VERSION ""

NS_ :

BS_:

BU_: AD_BATTERY_MONITOR LIGHT_ARRAY_REAR LIGHT_ARRAY_FRONT OBSTACLE_DETECTOR_REAR OBSTACLE_DETECTOR_FRONT WHEEL_REAR_RIGHT WHEEL_REAR_LEFT WHEEL_FRONT_RIGHT WHEEL_FRONT_LEFT SBUS_RECEIVER MOTOR SERVO BATTERY_MONITOR

BO_ 256 STEERING: 5 SBUS_RECEIVER
 SG_ STEERING_MODE M : 0|8@1+ (1,0) [0|0] "" Vector__XXX
 SG_ STEERING_PULSE_WIDTH m0 : 8|16@1+ (0.001,0) [500|2500] "ms" Vector__XXX
 SG_ STEERING_ANGLE m1 : 8|32@1- (1,0) [-90|90] "degrees" Vector__XXX

BO_ 257 THROTTLE: 5 SBUS_RECEIVER
 SG_ THROTTLE_MODE M : 0|8@1+ (1,0) [0|0] "" Vector__XXX
 SG_ THROTTLE_PULSE_WIDTH m0 : 8|16@1+ (0.001,0) [1000|2000] "ms" Vector__XXX

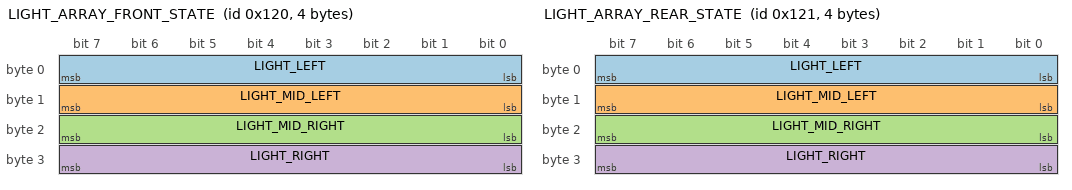
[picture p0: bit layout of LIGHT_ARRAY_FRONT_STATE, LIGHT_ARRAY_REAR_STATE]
BO_ 288 LIGHT_ARRAY_FRONT_STATE: 4 LIGHT_ARRAY_FRONT
 SG_ LIGHT_LEFT : 0|8@1+ (1,0) [0|0] "" Vector__XXX
 SG_ LIGHT_MID_LEFT : 8|8@1+ (1,0) [0|0] "" Vector__XXX
 SG_ LIGHT_MID_RIGHT : 16|8@1+ (1,0) [0|0] "" Vector__XXX
 SG_ LIGHT_RIGHT : 24|8@1+ (1,0) [0|0] "" Vector__XXX

BO_ 289 LIGHT_ARRAY_REAR_STATE: 4 LIGHT_ARRAY_REAR
 SG_ LIGHT_LEFT : 0|8@1+ (1,0) [0|0] "" Vector__XXX
 SG_ LIGHT_MID_LEFT : 8|8@1+ (1,0) [0|0] "" Vector__XXX
 SG_ LIGHT_MID_RIGHT : 16|8@1+ (1,0) [0|0] "" Vector__XXX
 SG_ LIGHT_RIGHT : 24|8@1+ (1,0) [0|0] "" Vector__XXX

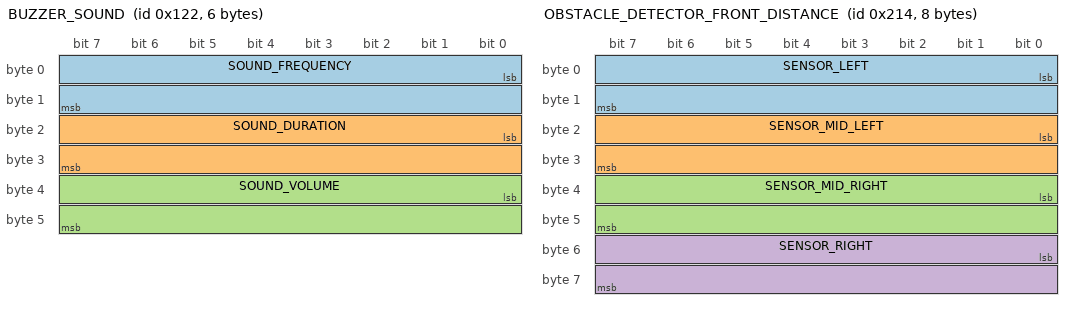
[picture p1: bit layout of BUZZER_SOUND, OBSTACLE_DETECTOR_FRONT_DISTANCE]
BO_ 290 BUZZER_SOUND: 6 Vector__XXX
 SG_ SOUND_FREQUENCY : 0|16@1+ (1,0) [0|0] "Hz" SBUS_RECEIVER
 SG_ SOUND_DURATION : 16|16@1+ (1,0) [0|0] "ms" SBUS_RECEIVER
 SG_ SOUND_VOLUME : 32|16@1+ (1,0) [0|0] "" SBUS_RECEIVER

BO_ 512 BATTERY_CELL_VOLTAGES: 7 BATTERY_MONITOR
 SG_ CELLS M : 0|8@1+ (1,0) [0|0] "" Vector__XXX
 SG_ CELL_1_VOLTAGE m0 : 8|16@1+ (1,0) [0|0] "mV" Vector__XXX
 SG_ CELL_2_VOLTAGE m0 : 24|16@1+ (1,0) [0|0] "mV" Vector__XXX
 SG_ CELL_3_VOLTAGE m0 : 40|16@1+ (1,0) [0|0] "mV" Vector__XXX
 SG_ CELL_4_VOLTAGE m1 : 8|16@1+ (1,0) [0|0] "mV" Vector__XXX
 SG_ CELL_5_VOLTAGE m1 : 24|16@1+ (1,0) [0|0] "mV" Vector__XXX
 SG_ CELL_6_VOLTAGE m1 : 40|16@1+ (1,0) [0|0] "mV" Vector__XXX

BO_ 513 REGULATED_OUTPUT: 8 Vector__XXX
 SG_ REGULATED_OUTPUT_VOLTAGE : 0|32@1+ (1,0) [0|0] "mV" Vector__XXX
 SG_ REGULATED_OUTPUT_CURRENT : 32|32@1+ (1,0) [0|0] "mA" Vector__XXX

BO_ 514 BATTERY_OUTPUT: 8 BATTERY_MONITOR
 SG_ BATTERY_OUTPUT_VOLTAGE : 0|32@1+ (1,0) [0|0] "mV" Vector__XXX
 SG_ BATTERY_OUTPUT_CURRENT : 32|32@1+ (1,0) [0|0] "mA" Vector__XXX

BO_ 515 SERVO_VOLTAGE: 2 SERVO
 SG_ SERVO_VOLTAGE : 0|16@1+ (1,0) [0|0] "mV" Vector__XXX

BO_ 516 SERVO_CURRENT: 2 SERVO
 SG_ SERVO_CURRENT : 0|16@1+ (1,0) [0|0] "mA" Vector__XXX

BO_ 517 BATTERY_VOLTAGE: 2 BATTERY_MONITOR
 SG_ BATTERY_VOLTAGE : 0|16@1+ (1,0) [0|0] "mV" Vector__XXX

BO_ 518 SERVO_POSITION: 4 SERVO
 SG_ SERVO_POSITION : 0|32@1- (1,0) [0|0] "degrees" Vector__XXX

BO_ 528 WHEEL_FRONT_LEFT_SPEED: 8 WHEEL_FRONT_LEFT
 SG_ RPM : 0|32@1- (1,0) [0|0] "" Vector__XXX
 SG_ SPEED : 32|32@1- (1,0) [0|0] "km/h" Vector__XXX

BO_ 529 WHEEL_FRONT_RIGHT_SPEED: 8 WHEEL_FRONT_RIGHT
 SG_ RPM : 0|32@1- (1,0) [0|0] "" Vector__XXX
 SG_ SPEED : 32|32@1- (1,0) [0|0] "km/h" Vector__XXX

BO_ 530 WHEEL_REAR_LEFT_SPEED: 8 WHEEL_REAR_LEFT
 SG_ RPM : 0|32@1- (1,0) [0|0] "" Vector__XXX
 SG_ SPEED : 32|32@1- (1,0) [0|0] "km/h" Vector__XXX

BO_ 531 WHEEL_REAR_RIGHT_SPEED: 8 WHEEL_REAR_RIGHT
 SG_ RPM : 0|32@1- (1,0) [0|0] "" Vector__XXX
 SG_ SPEED : 32|32@1- (1,0) [0|0] "km/h" Vector__XXX

BO_ 532 OBSTACLE_DETECTOR_FRONT_DISTANCE: 8 OBSTACLE_DETECTOR_FRONT
 SG_ SENSOR_LEFT : 0|16@1+ (1,0) [0|0] "mm" Vector__XXX
 SG_ SENSOR_MID_LEFT : 16|16@1+ (1,0) [0|0] "mm" Vector__XXX
 SG_ SENSOR_MID_RIGHT : 32|16@1+ (1,0) [0|0] "mm" Vector__XXX
 SG_ SENSOR_RIGHT : 48|16@1+ (1,0) [0|0] "mm" Vector__XXX

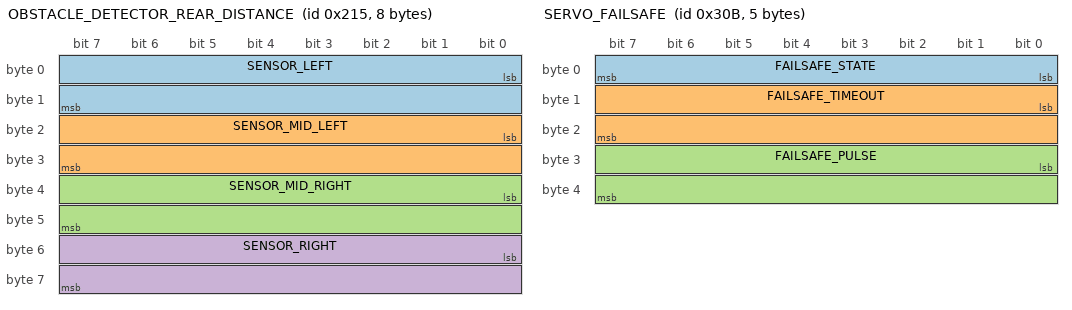
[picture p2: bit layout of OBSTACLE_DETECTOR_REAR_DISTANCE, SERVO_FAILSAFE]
BO_ 533 OBSTACLE_DETECTOR_REAR_DISTANCE: 8 OBSTACLE_DETECTOR_REAR
 SG_ SENSOR_LEFT : 0|16@1+ (1,0) [0|0] "mm" Vector__XXX
 SG_ SENSOR_MID_LEFT : 16|16@1+ (1,0) [0|0] "mm" Vector__XXX
 SG_ SENSOR_MID_RIGHT : 32|16@1+ (1,0) [0|0] "mm" Vector__XXX
 SG_ SENSOR_RIGHT : 48|16@1+ (1,0) [0|0] "mm" Vector__XXX

BO_ 768 BATTERY_JUMPER_CONFIG: 1 Vector__XXX
 SG_ JUMPER_CONFIG : 0|8@1+ (1,0) [0|0] ""  BATTERY_MONITOR

BO_ 769 BATTERY_REGULATED_OUTPUT_VOLTAGE: 4 Vector__XXX
 SG_ REGULATED_OUTPUT_VOLTAGE : 0|32@1+ (1,0) [0|0] "mV"  BATTERY_MONITOR

BO_ 770 BATTERY_OUTPUT_ON_OFF: 2 Vector__XXX
 SG_ MAIN_POWER_OUTPUT_STATE : 0|8@1+ (1,0) [0|0] ""  BATTERY_MONITOR
 SG_ REGULATED_OUTPUT_STATE : 8|8@1+ (1,0) [0|0] ""  BATTERY_MONITOR

BO_ 771 BATTERY_REPORT_FREQUENCY: 2 Vector__XXX
 SG_ REPORT_PERIOD : 0|16@1+ (1,0) [0|0] "ms"  BATTERY_MONITOR

BO_ 772 BATTERY_LOW_VOLTAGE_CUTOFF: 2 Vector__XXX
 SG_ LOW_VOLTAGE_CUTOFF : 0|16@1+ (1,0) [0|0] "mV"  BATTERY_MONITOR

BO_ 773 SERVO_SET_VOLTAGE: 2 Vector__XXX
 SG_ REQUESTED_SERVO_VOLTAGE : 0|16@1+ (1,0) [2740|10800] "mV"  SERVO

BO_ 774 SERVO_PWM_CONFIG: 2 Vector__XXX
 SG_ PWM_FREQUENCY : 0|16@1+ (1,0) [1|333] "Hz"  SERVO

BO_ 775 SERVO_REPORT_FREQUENCY: 2 Vector__XXX
 SG_ REPORT_PERIOD : 0|16@1+ (1,0) [0|0] "ms"  SERVO

BO_ 776 MOTOR_PWM_CONFIG: 2 Vector__XXX
 SG_ PWM_FREQUENCY : 0|16@1+ (1,0) [1|333] "Hz"  MOTOR

BO_ 777 SERVO_REVERSE_DIRECTION: 0 Vector__XXX

BO_ 778 MOTOR_REVERSE_DIRECTION: 0 Vector__XXX

BO_ 779 SERVO_FAILSAFE: 5 Vector__XXX
 SG_ FAILSAFE_STATE : 0|8@1+ (1,0) [0|0] ""  SERVO
 SG_ FAILSAFE_TIMEOUT : 8|16@1+ (1,0) [0|0] "ms"  SERVO
 SG_ FAILSAFE_PULSE : 24|16@1+ (0.001,0) [500|2500] "ms"  SERVO

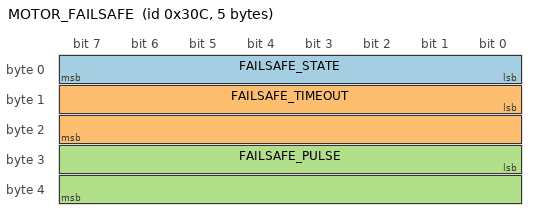
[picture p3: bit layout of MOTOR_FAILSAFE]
BO_ 780 MOTOR_FAILSAFE: 5 Vector__XXX
 SG_ FAILSAFE_STATE : 0|8@1+ (1,0) [0|0] ""  MOTOR
 SG_ FAILSAFE_TIMEOUT : 8|16@1+ (1,0) [0|0] "ms"  MOTOR
 SG_ FAILSAFE_PULSE : 24|16@1+ (0.001,0) [1000|2000] "ms"  MOTOR

BO_ 781 STEERING_SUBTRIM: 2 Vector__XXX
 SG_ SUBTRIM : 0|16@1- (0.001,0) [-500|500] "ms" Vector__XXX

BO_ 782 THROTTLE_SUBTRIM: 2 Vector__XXX
 SG_ SUBTRIM : 0|16@1- (0.001,0) [-500|500] "ms" Vector__XXX

BO_ 783 BATTERY_VBAT_OUT_OVERCURRENT_THRESHOLD: 4 Vector__XXX
 SG_ OVERCURRENT_THRESHOLD : 0|32@1+ (1,0) [0|0] "mA"  BATTERY_MONITOR

BO_ 784 BATTERY_REG_OUT_OVERCURRENT_THRESHOLD: 4 Vector__XXX
 SG_ OVERCURRENT_THRESHOLD : 0|32@1+ (1,0) [0|0] "mA"  BATTERY_MONITOR

BO_ 785 WHEEL_FRONT_LEFT_WHEEL_PARAMETERS: 8 Vector__XXX
 SG_ COG_COUNT : 0|32@1+ (1,0) [0|0] ""  WHEEL_FRONT_LEFT
 SG_ WHEEL_DIAMETER : 32|32@1- (1,0) [0|0] "m"  WHEEL_FRONT_LEFT

BO_ 786 WHEEL_FRONT_LEFT_REPORT_FREQUENCY: 2 Vector__XXX
 SG_ REPORT_PERIOD : 0|16@1+ (1,0) [0|0] "ms"  WHEEL_FRONT_LEFT

BO_ 787 WHEEL_FRONT_RIGHT_WHEEL_PARAMETERS: 8 Vector__XXX
 SG_ COG_COUNT : 0|32@1+ (1,0) [0|0] ""  WHEEL_FRONT_RIGHT
 SG_ WHEEL_DIAMETER : 32|32@1- (1,0) [0|0] "m"  WHEEL_FRONT_RIGHT

BO_ 788 WHEEL_FRONT_RIGHT_REPORT_FREQUENCY: 2 Vector__XXX
 SG_ REPORT_PERIOD : 0|16@1+ (1,0) [0|0] "ms"  WHEEL_FRONT_RIGHT

BO_ 789 WHEEL_REAR_LEFT_WHEEL_PARAMETERS: 8 Vector__XXX
 SG_ COG_COUNT : 0|32@1+ (1,0) [0|0] ""  WHEEL_REAR_LEFT
 SG_ WHEEL_DIAMETER : 32|32@1- (1,0) [0|0] "m"  WHEEL_REAR_LEFT

BO_ 790 WHEEL_REAR_LEFT_REPORT_FREQUENCY: 2 Vector__XXX
 SG_ REPORT_PERIOD : 0|16@1+ (1,0) [0|0] "ms"  WHEEL_REAR_LEFT

BO_ 791 WHEEL_REAR_RIGHT_WHEEL_PARAMETERS: 8 Vector__XXX
 SG_ COG_COUNT : 0|32@1+ (1,0) [0|0] ""  WHEEL_REAR_RIGHT
 SG_ WHEEL_DIAMETER : 32|32@1- (1,0) [0|0] "m"  WHEEL_REAR_RIGHT

BO_ 792 WHEEL_REAR_RIGHT_REPORT_FREQUENCY: 2 Vector__XXX
 SG_ REPORT_PERIOD : 0|16@1+ (1,0) [0|0] "ms"  WHEEL_REAR_RIGHT

BO_ 793 BATTERY_CELL_CALIBRATION: 2 Vector__XXX
 SG_ CELL_CALIBRATION_VOLTAGE : 0|16@1+ (1,0) [0|0] "mV"  BATTERY_MONITOR

BO_ 794 OBSTACLE_DETECTOR_FRONT_REPORT_FREQUENCY: 2 Vector__XXX
 SG_ REPORT_PERIOD : 0|16@1+ (1,0) [0|0] "ms"  OBSTACLE_DETECTOR_FRONT

BO_ 795 OBSTACLE_DETECTOR_REAR_REPORT_FREQUENCY: 2 Vector__XXX
 SG_ REPORT_PERIOD : 0|16@1+ (1,0) [0|0] "ms"  OBSTACLE_DETECTOR_REAR

BO_ 1792 BOOTLOADER_COMMAND_ACK: 5 Vector__XXX
 SG_ ACK_TYPE : 0|8@1+ (1,0) [0|0] "" Vector__XXX
 SG_ COMMAND_ID : 8|32@1+ (1,0) [0|0] "" Vector__XXX

BO_ 1793 BOOTLOADER_ENTER: 0 Vector__XXX

BO_ 1794 BOOTLOADER_EXIT: 0 Vector__XXX

BO_ 1795 BOOTLOADER_FLASH_ERASE: 4 Vector__XXX
 SG_ BYTES : 0|32@1+ (1,0) [0|0] "bytes" Vector__XXX

BO_ 1796 BOOTLOADER_FORMAT_FS: 0 Vector__XXX

BO_ 1797 BOOTLOADER_FLASH_PROGRAM: 8 Vector__XXX
 SG_ BLOCK_TRANSFER_PAGE M : 0|8@1+ (1,0) [0|0] "" Vector__XXX
 SG_ BLOCK_LENGTH m1 : 8|32@1+ (1,0) [0|0] "bytes" Vector__XXX
 SG_ BUNDLE_PAGE_COUNT m2 : 8|16@1+ (1,0) [0|0] "" Vector__XXX
 SG_ DATA_A m3 : 8|56@1+ (1,0) [0|0] "" Vector__XXX
 SG_ DATA_B m4 : 8|56@1+ (1,0) [0|0] "" Vector__XXX

BO_ 1798 BOOTLOADER_FLASH_CONFIG: 8 Vector__XXX
 SG_ BLOCK_TRANSFER_PAGE M : 0|8@1+ (1,0) [0|0] "" Vector__XXX
 SG_ BLOCK_LENGTH m1 : 8|32@1+ (1,0) [0|0] "bytes" Vector__XXX
 SG_ BUNDLE_PAGE_COUNT m2 : 8|16@1+ (1,0) [0|0] "" Vector__XXX
 SG_ DATA_A m3 : 8|56@1+ (1,0) [0|0] "" Vector__XXX
 SG_ DATA_B m4 : 8|56@1+ (1,0) [0|0] "" Vector__XXX

BO_ 1280 AD_BATTERY_CELL_VOLTAGES: 7 AD_BATTERY_MONITOR
 SG_ CELLS M : 0|8@1+ (1,0) [0|0] "" Vector__XXX
 SG_ CELL_1_VOLTAGE m0 : 8|16@1+ (1,0) [0|0] "mV" Vector__XXX
 SG_ CELL_2_VOLTAGE m0 : 24|16@1+ (1,0) [0|0] "mV" Vector__XXX
 SG_ CELL_3_VOLTAGE m0 : 40|16@1+ (1,0) [0|0] "mV" Vector__XXX
 SG_ CELL_4_VOLTAGE m1 : 8|16@1+ (1,0) [0|0] "mV" Vector__XXX
 SG_ CELL_5_VOLTAGE m1 : 24|16@1+ (1,0) [0|0] "mV" Vector__XXX
 SG_ CELL_6_VOLTAGE m1 : 40|16@1+ (1,0) [0|0] "mV" Vector__XXX

BO_ 1281 AD_REGULATED_OUTPUT: 8 AD_BATTERY_MONITOR
 SG_ REGULATED_OUTPUT_VOLTAGE : 0|32@1+ (1,0) [0|0] "mV" Vector__XXX
 SG_ REGULATED_OUTPUT_CURRENT : 32|32@1+ (1,0) [0|0] "mA" Vector__XXX

BO_ 1282 AD_BATTERY_OUTPUT: 8 AD_BATTERY_MONITOR
 SG_ BATTERY_OUTPUT_VOLTAGE : 0|32@1+ (1,0) [0|0] "mV" Vector__XXX
 SG_ BATTERY_OUTPUT_CURRENT : 32|32@1+ (1,0) [0|0] "mA" Vector__XXX

BO_ 1283 AD_BATTERY_VOLTAGE: 2 AD_BATTERY_MONITOR
 SG_ BATTERY_VOLTAGE : 0|16@1+ (1,0) [0|0] "mV" Vector__XXX

BO_ 1536 AD_BATTERY_JUMPER_CONFIG: 1 Vector__XXX
 SG_ JUMPER_CONFIG : 0|8@1+ (1,0) [0|0] ""  AD_BATTERY_MONITOR

BO_ 1537 AD_BATTERY_REGULATED_OUTPUT_VOLTAGE: 4 Vector__XXX
 SG_ REGULATED_OUTPUT_VOLTAGE : 0|32@1+ (1,0) [0|0] "mV"  AD_BATTERY_MONITOR

BO_ 1538 AD_BATTERY_OUTPUT_ON_OFF: 2 Vector__XXX
 SG_ MAIN_POWER_OUTPUT_STATE : 0|8@1+ (1,0) [0|0] ""  AD_BATTERY_MONITOR
 SG_ REGULATED_OUTPUT_STATE : 8|8@1+ (1,0) [0|0] ""  AD_BATTERY_MONITOR

BO_ 1539 AD_BATTERY_REPORT_FREQUENCY: 2 Vector__XXX
 SG_ REPORT_PERIOD : 0|16@1+ (1,0) [0|0] "ms"  AD_BATTERY_MONITOR

BO_ 1540 AD_BATTERY_LOW_VOLTAGE_CUTOFF: 2 Vector__XXX
 SG_ LOW_VOLTAGE_CUTOFF : 0|16@1+ (1,0) [0|0] "mV"  AD_BATTERY_MONITOR

BO_ 1551 AD_BATTERY_VBAT_OUT_OVERCURRENT_THRESHOLD: 4 Vector__XXX
 SG_ OVERCURRENT_THRESHOLD : 0|32@1+ (1,0) [0|0] "mA"  AD_BATTERY_MONITOR

BO_ 1552 AD_BATTERY_REG_OUT_OVERCURRENT_THRESHOLD: 4 Vector__XXX
 SG_ OVERCURRENT_THRESHOLD : 0|32@1+ (1,0) [0|0] "mA"  AD_BATTERY_MONITOR

BO_ 1553 AD_BATTERY_CELL_CALIBRATION: 2 Vector__XXX
 SG_ CELL_CALIBRATION_VOLTAGE : 0|16@1+ (1,0) [0|0] "mV"  AD_BATTERY_MONITOR

VAL_ 256 STEERING_MODE 0 "PULSE_WIDTH_MODE" 1 "ANGLE_MODE" ;
VAL_ 257 THROTTLE_MODE 0 "PULSE_WIDTH_MODE" ;
VAL_ 288 LIGHT_LEFT 0 "OFF" 1 "ON" ;
VAL_ 288 LIGHT_MID_LEFT 0 "OFF" 1 "ON" ;
VAL_ 288 LIGHT_MID_RIGHT 0 "OFF" 1 "ON" ;
VAL_ 288 LIGHT_RIGHT 0 "OFF" 1 "ON" ;
VAL_ 289 LIGHT_LEFT 0 "OFF" 1 "ON" ;
VAL_ 289 LIGHT_MID_LEFT 0 "OFF" 1 "ON" ;
VAL_ 289 LIGHT_MID_RIGHT 0 "OFF" 1 "ON" ;
VAL_ 289 LIGHT_RIGHT 0 "OFF" 1 "ON" ;
VAL_ 512 CELLS 0 "CELLS_1_TO_3" 1 "CELLS_4_TO_6" ;
VAL_ 768 JUMPER_CONFIG 0 "X11_OFF_X12_OFF" 1 "X11_ON_X12_OFF" 2 "X11_OFF_X12_ON" 3 "X11_ON_X12_ON" ;
VAL_ 770 MAIN_POWER_OUTPUT_STATE 0 "OFF" 1 "ON" ;
VAL_ 770 REGULATED_OUTPUT_STATE 0 "OFF" 1 "ON" ;
VAL_ 779 FAILSAFE_STATE 0 "OFF" 1 "ON" ;
VAL_ 780 FAILSAFE_STATE 0 "OFF" 1 "ON" ;
VAL_ 1792 ACK_TYPE 0 "ACK" 1 "NACK" ;
VAL_ 1797 BLOCK_TRANSFER_PAGE 0 "REQUEST_PAGE" 1 "SETUP_PAGE" 2 "BUNDLE_REQUEST_PAGE" 3 "DATA_PAGE" 4 "DATA_PAGE" 5 "ABORT_PAGE" ;
VAL_ 1798 BLOCK_TRANSFER_PAGE 0 "REQUEST_PAGE" 1 "SETUP_PAGE" 2 "BUNDLE_REQUEST_PAGE" 3 "DATA_PAGE" 4 "DATA_PAGE" 5 "ABORT_PAGE" ;
VAL_ 1280 CELLS 0 "CELLS_1_TO_3" 1 "CELLS_4_TO_6" ;
VAL_ 1536 JUMPER_CONFIG 0 "X11_OFF_X12_OFF" 1 "X11_ON_X12_OFF" 2 "X11_OFF_X12_ON" 3 "X11_ON_X12_ON" ;
VAL_ 1538 MAIN_POWER_OUTPUT_STATE 0 "OFF" 1 "ON" ;
VAL_ 1538 REGULATED_OUTPUT_STATE 0 "OFF" 1 "ON" ;
SIG_VALTYPE_ 256 STEERING_ANGLE : 1;
SIG_VALTYPE_ 518 SERVO_POSITION : 1;
SIG_VALTYPE_ 528 RPM : 1;
SIG_VALTYPE_ 528 SPEED : 1;
SIG_VALTYPE_ 529 RPM : 1;
SIG_VALTYPE_ 529 SPEED : 1;
SIG_VALTYPE_ 530 RPM : 1;
SIG_VALTYPE_ 530 SPEED : 1;
SIG_VALTYPE_ 531 RPM : 1;
SIG_VALTYPE_ 531 SPEED : 1;
SIG_VALTYPE_ 785 WHEEL_DIAMETER : 1;
SIG_VALTYPE_ 787 WHEEL_DIAMETER : 1;
SIG_VALTYPE_ 789 WHEEL_DIAMETER : 1;
SIG_VALTYPE_ 791 WHEEL_DIAMETER : 1;
